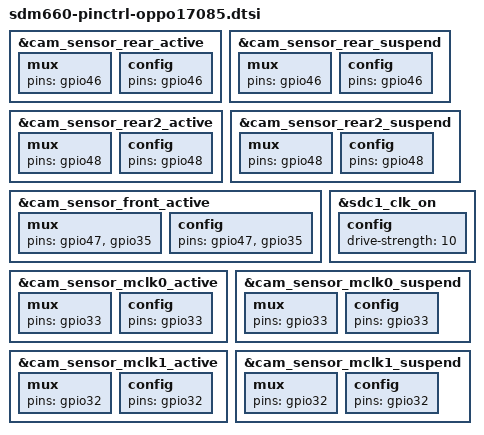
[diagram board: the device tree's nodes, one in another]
/* OPPO 17085 pinctrl overrides — correct VENDOR_EDIT values */

&cam_sensor_rear_active {
	mux { pins = "gpio46"; };
	config { pins = "gpio46"; };
};

&cam_sensor_rear_suspend {
	mux { pins = "gpio46"; };
	config { pins = "gpio46"; };
};

&cam_sensor_rear2_active {
	mux { pins = "gpio48"; };
	config { pins = "gpio48"; };
};

&cam_sensor_rear2_suspend {
	mux { pins = "gpio48"; };
	config { pins = "gpio48"; };
};

&cam_sensor_front_active {
	mux { pins = "gpio47", "gpio35"; };
	config { pins = "gpio47", "gpio35"; };
};

&sdc1_clk_on {
	config { drive-strength = <10>; };
};

&cam_sensor_mclk0_active {
	mux { pins = "gpio33"; };
	config { pins = "gpio33"; };
};

&cam_sensor_mclk0_suspend {
	mux { pins = "gpio33"; };
	config { pins = "gpio33"; };
};

&cam_sensor_mclk1_active {
	mux { pins = "gpio32"; };
	config { pins = "gpio32"; };
};

&cam_sensor_mclk1_suspend {
	mux { pins = "gpio32"; };
	config { pins = "gpio32"; };
};

